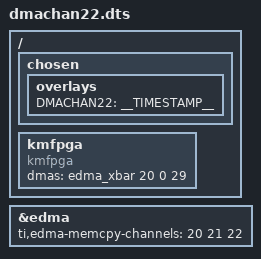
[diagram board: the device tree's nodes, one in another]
/dts-v1/;
/plugin/;

#include <dt-bindings/gpio/gpio.h>
#include <dt-bindings/pinctrl/am33xx.h>
#include <dt-bindings/board/am335x-bone-pins.h>

/ {
    /*
     * Helper to show loaded overlays under: /proc/device-tree/chosen/overlays/
     */

    fragment@0 {
        target-path="/";
        __overlay__ {

            chosen {
                overlays {
                    DMACHAN22 = __TIMESTAMP__;
                };
            };
        };
    };


    fragment@1 {
        target-path="/";
        __overlay__ {
            kmfpga {
                compatible = "kmfpga";
                status = "okay";
//                dmas = <&edma 22 0>;
                dmas = <&edma_xbar 20 0 29>;
                dma-names = "kmfpga_evt";
            };
        };
    };

/*
    fragment@2 {
        target = <&am33xx_pinmux>;
        __overlay__ {
            P9_41_default_pin: pinmux_P9_41_default_pin { pinctrl-single,pins = <
                P9_41( PIN_OUTPUT_PULLDOWN | INPUT_EN | MUX_MODE0) >; };
        };
    };
*/
    /*
     * Free up the pins used by the cape from the pinmux helpers.
     */
/*
    fragment@1 {
        target = <&ocp>;
        __overlay__ {
            P8_07_pinmux { status = "disabled"; };  // gpio2_2.timer4

            gpevt {
                compatible = "gpevt";
//                pinctrl-0 = <&gpevt_pins_s0>;
                dmas = <&edma 12>;
//                dmas = <&edma 22>;
//                dmas = <&edma_xbar 12 0 32>;
                dma-names = "gpioevt";
                gpio-evt = <&gpio1 7 0>;
            };
        };
    };
*/
/*
    fragment@2 {
        target = <&am33xx_pinmux>;
        __overlay__ {
            gpevt_pins_s0: gpevt_pins_s0 {
                pinctrl-single,pins = <
                    AM33XX_IOPAD(0x0890, PIN_OUTPUT_PULLUP | INPUT_EN | MUX_MODE7)
                >;
            };
        };
    };
*/

    fragment@3 {
        target = <&edma>;
        __overlay__ {
            ti,edma-memcpy-channels = <20 21 22>;
        };
    };

/*
    fragment@20 {
        target-path="/";
        __overlay__ {

            gpio_keys {
                compatible = "gpio-keys";
                pinctrl-names = "default";
                pinctrl-0 = <&gpevt_pins_s0>;
            };
        };
    };
*/
};
